# ATmega64HVE2 device description
Architecture: AVR8; Family: megaAVR
Registers are 8-bit, access not given, no defined reset value unless marked. A register's access mark holds for its fields unless they carry their own. Offsets are from the block's base; [hi:lo] are bit positions.

## BANDGAP
Instances: BANDGAP 0x00
0xD1 BGCSRA — Bandgap Control and Status Register A
  [2:0] BGSC — Band Gap Sample Configuration
0xD2 BGCRB — Band Gap Calibration Register B
  [7:0] BGCL — Band Gap Calibration Linear
0xD3 BGCRA — Band Gap Calibration Register A
  [7:0] BGCN — Band Gap Calibration Nominal
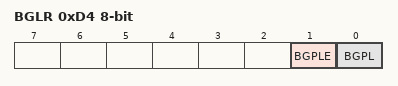
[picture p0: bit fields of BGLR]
0xD4 BGLR — Band Gap Lock Register
  [1] BGPLE — Band Gap Lock Enable
  [0] BGPL — Band Gap Lock

## LINUART — Local Interconnect Network
Instances: LINUART 0x00
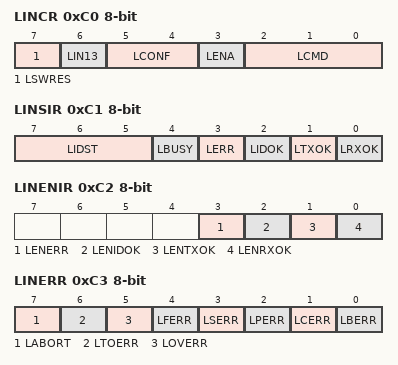
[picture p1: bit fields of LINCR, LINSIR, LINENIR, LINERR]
0xC0 LINCR — LIN Control Register
  [7] LSWRES — Software Reset
  [6] LIN13 — LIN Standard
  [5:4] LCONF — LIN Configuration bits
  [3] LENA — LIN or UART Enable
  [2:0] LCMD — LIN Command and Mode bits
0xC1 LINSIR — LIN Status and Interrupt Register
  [7:5] LIDST — Identifier Status bits
  [4] LBUSY — Busy Signal
  [3] LERR — Error Interrupt
  [2] LIDOK — Identifier Interrupt
  [1] LTXOK — Transmit Performed Interrupt
  [0] LRXOK — Receive Performed Interrupt
0xC2 LINENIR — LIN Enable Interrupt Register
  [3] LENERR — Enable Error Interrupt
  [2] LENIDOK — Enable Identifier Interrupt
  [1] LENTXOK — Enable Transmit Performed Interrupt
  [0] LENRXOK — Enable Receive Performed Interrupt
0xC3 LINERR — LIN Error Register
  [7] LABORT — Abort Flag
  [6] LTOERR — Frame Time Out Error Flag
  [5] LOVERR — Overrun Error Flag
  [4] LFERR — Framing Error Flag
  [3] LSERR — Synchronization Error Flag
  [2] LPERR — Parity Error Flag
  [1] LCERR — Checksum Error Flag
  [0] LBERR — Bit Error Flag
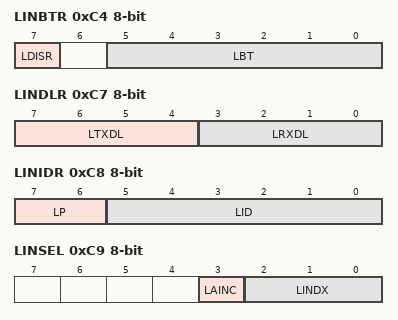
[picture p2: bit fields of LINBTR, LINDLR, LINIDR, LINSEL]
0xC4 LINBTR — LIN Bit Timing Register
  [7] LDISR — Disable Bit Timing Resynchronization
  [5:0] LBT — LIN Bit Timing bits
0xC5 LINBRRL — LIN Baud Rate Low Register
  [7:0] LDIV
0xC6 LINBRRH — LIN Baud Rate High Register
  [3:0] LDIV (bit 8 of the value upward)
0xC7 LINDLR — LIN Data Length Register
  [7:4] LTXDL — LIN Transmit Data Length bits
  [3:0] LRXDL — LIN Receive Data Length bits
0xC8 LINIDR — LIN Identifier Register
  [7:6] LP — Parity bits
  [5:0] LID — Identifier bit 5 or Data Length bits
0xC9 LINSEL — LIN Data Buffer Selection Register
  [3] LAINC — Auto Increment of Data Buffer Index (Active Low)
  [2:0] LINDX — FIFO LIN Data Buffer Index bits
0xCA LINDAT — LIN Data Register
  [7:0] LDATA

## CPU — CPU Registers
Instances: CPU 0x00
Parameters: CORE_VERSION=V2E
0x3E GPIOR0 — General Purpose IO Register 0
0x4A GPIOR1 — General Purpose IO Register 1
0x4B GPIOR2 — General Purpose IO Register 2
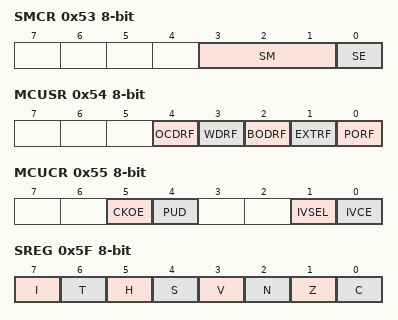
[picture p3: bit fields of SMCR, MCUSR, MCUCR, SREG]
0x53 SMCR — Sleep Mode Control Register
  [3:1] SM — Sleep Mode Select bits
    0=IDLE; 1=ADC; 2=PDOWN (Power Down); 3=PSAVE (Power Save); 6=STDBY (Standby); 7=ESTDBY (Extended Standby)
  [0] SE — Sleep Enable
0x54 MCUSR — MCU Status Register
  [4] OCDRF — OCD Reset Flag
  [3] WDRF — Watchdog Reset Flag
  [2] BODRF — Brown-out Reset Flag
  [1] EXTRF — External Reset Flag
  [0] PORF — Power-on reset flag
0x55 MCUCR — MCU Control Register
  [5] CKOE — Clock Output Enable
  [4] PUD — Pull-up disable
  [1] IVSEL — Interrupt Vector Select
  [0] IVCE — Interrupt Vector Change Enable
0x5D SP 16-bit — Stack Pointer
0x5F SREG — Status Register
  [7] I — Global Interrupt Enable
  [6] T — Bit Copy Storage
  [5] H — Half Carry Flag
  [4] S — Sign Bit
  [3] V — Two's Complement Overflow Flag
  [2] N — Negative Flag
  [1] Z — Zero Flag
  [0] C — Carry Flag
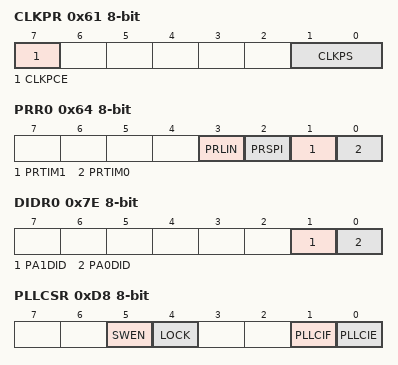
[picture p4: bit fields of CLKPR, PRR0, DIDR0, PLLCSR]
0x61 CLKPR — Clock Prescale Register
  [7] CLKPCE — Clock Prescaler Change Enable
  [1:0] CLKPS — Clock Prescaler Select Bits
0x64 PRR0 — Power Reduction Register 0
  [3] PRLIN — Power Reduction LIN UART Interface
  [2] PRSPI — Power reduction SPI
  [1] PRTIM1 — Power Reduction Timer/Counter1
  [0] PRTIM0 — Power Reduction Timer/Counter0
0x66 SOSCCALA — Slow Oscillator Calibration Register A
0x67 SOSCCALB — Oscillator Calibration Register B
0x7E DIDR0 — Digital Input Disable Register
  [1] PA1DID — When this bit is written logic one, the digital input buffer of the corresponding V_ADC pin is disabled.
  [0] PA0DID — When this bit is written logic one, the digital input buffer of the corresponding V_ADC pin is disabled.
0xD8 PLLCSR — PLL Control and Status Register
  [5] SWEN — PLL Software Enable
  [4] LOCK — PLL Lock
  [1] PLLCIF — PLL Lock Change Interrupt Flag
  [0] PLLCIE — PLL Lock Change Interrupt Enable

## EXINT — External Interrupts
Instances: EXINT 0x00
0x3B PCIFR — Pin Change Interrupt Flag Register
  [1:0] PCIF — Pin Change Interrupt Flags
0x3C EIFR — External Interrupt Flag Register
  [0] INTF0 — External Interrupt Flag 0
0x3D EIMSK — External Interrupt Mask Register
  [0] INT0 — External Interrupt Request 0 Enable
0x68 PCICR — Pin Change Interrupt Control Register
  [1:0] PCIE — Pin Change Interrupt Enables
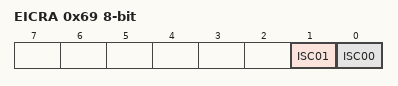
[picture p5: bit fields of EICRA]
0x69 EICRA — External Interrupt Control Register
  [1] ISC01 — External Interrupt Sense Control 0 Bit 1
  [0] ISC00 — External Interrupt Sense Control 0 Bit 0
    0=Low Level of INTX; 1=Any Logical Change of INTX; 2=Falling Edge of INTX; 3=Rising Edge of INTX
0x6B PCMSK0 bits used 1:0 — Pin Change Enable Mask Register 0
0x6C PCMSK1 — Pin Change Enable Mask Register 1

## WDT — Watchdog Timer
Instances: WDT 0x00
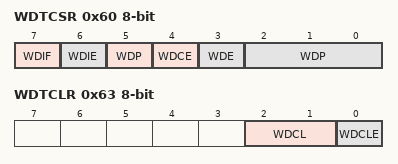
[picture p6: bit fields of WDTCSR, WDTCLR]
0x60 WDTCSR — Watchdog Timer Control Register
  [7] WDIF — Watchdog Timeout Interrupt Flag
  [6] WDIE — Watchdog Timeout Interrupt Enable
  [4] WDCE — Watchdog Change Enable
  [3] WDE — Watch Dog Enable
  [5,2:0] WDP — Watchdog Timer Prescaler Bits
    0=Oscillator Cycles 2K; 1=Oscillator Cycles 4K; 2=Oscillator Cycles 8K; 3=Oscillator Cycles 16K; 4=Oscillator Cycles 32K; 5=Oscillator Cycles 64K; 6=Oscillator Cycles 128K; 7=Oscillator Cycles 256K; 8=Oscillator Cycles 512K; 9=Oscillator Cycles 1024K
0x63 WDTCLR — Watchdog Timer Configuration Lock Register
  [2:1] WDCL — Watchdog Timer Comfiguration Lock bits
  [0] WDCLE — Watchdog Timer Comfiguration Lock Enable

## WAKEUP_TIMER
Instances: WAKEUP_TIMER 0x00
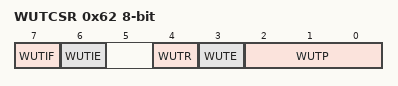
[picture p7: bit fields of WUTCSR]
0x62 WUTCSR — Wake-up Timer Control and Status Register
  [7] WUTIF — Wake-up Timer Interrupt Flag
  [6] WUTIE — Wake-up Timer Interrupt Enable
  [4] WUTR — Wake-up Timer Reset
  [3] WUTE — Wake-up Timer Enable
  [2:0] WUTP — Wake-up Timer Prescaler Bits
